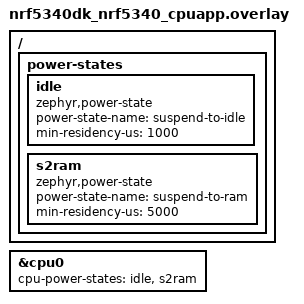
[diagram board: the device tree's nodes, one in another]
/*
 * Copyright (c) 2022 Carlo Caione <ccaione@baylibre.com>
 *
 * SPDX-License-Identifier: Apache-2.0
 */

/ {
	power-states {
		idle: idle {
			compatible = "zephyr,power-state";
			power-state-name = "suspend-to-idle";
			min-residency-us = <1000>;
		};

		s2ram: s2ram {
			compatible = "zephyr,power-state";
			power-state-name = "suspend-to-ram";
			min-residency-us = <5000>;
		};
	};
};

&cpu0 {
	cpu-power-states = <&idle &s2ram>;
};
